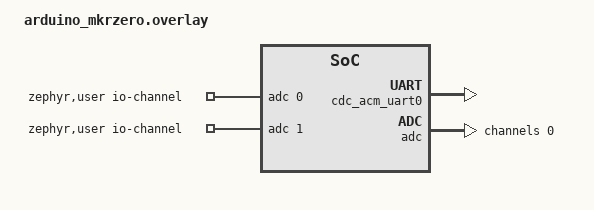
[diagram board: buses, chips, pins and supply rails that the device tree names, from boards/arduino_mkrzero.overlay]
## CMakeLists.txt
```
cmake_minimum_required(VERSION 3.20.0)

find_package(Zephyr)
project(desktop_display)

target_sources(app PRIVATE
        src/main.c
        src/drivers/lcd/lcd.c
        src/serialdata.c
)

target_include_directories(app PRIVATE src)
```

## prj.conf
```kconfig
# Enable UART driver
CONFIG_SERIAL=y

# Enable console but use USB CDC-ACM instead of UART
CONFIG_STDOUT_CONSOLE=n
CONFIG_UART_CONSOLE=y
CONFIG_UART_INTERRUPT_DRIVEN=y

# Enable USB device stack
CONFIG_USB_DEVICE_STACK=y
CONFIG_USB_DEVICE_PRODUCT="Arduino MKR Zero"
CONFIG_USB_DEVICE_MANUFACTURER="Zephyr"
CONFIG_USB_DEVICE_PID=0x0001

# Enable logging for debugging
CONFIG_LOG=y
CONFIG_LOG_DEFAULT_LEVEL=3

# Enable GPIO (we'll need this later for LCD)
CONFIG_GPIO=y

CONFIG_ADC=y
CONFIG_ADC_ASYNC=n
CONFIG_ADC_INIT_PRIORITY=99

CONFIG_USB_DEVICE_INITIALIZE_AT_BOOT=n

CONFIG_CBPRINTF_FP_SUPPORT=y
```

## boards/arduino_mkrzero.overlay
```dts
/*
 * Arduino MKR Zero overlay for LCD keypad project
 */

&zephyr_udc0 {
	cdc_acm_uart0 {
		compatible = "zephyr,cdc-acm-uart";
		label = "Zephyr USB CDC-ACM";
	};
};

/ {
	aliases {
		adc0 = &adc;
	};
};

/ {
	zephyr,user {
		/* Reference the ADC channel for keypad reading */
		io-channels = <&adc 0>, <&adc 1>;
	};
};

&adc {
	#address-cells = <1>;
	#size-cells = <0>;
	status = "okay";

	/* ADC channel configuration for keypad */
	channel@0 {
		reg = <0>;
		zephyr,gain = "ADC_GAIN_2";
		zephyr,reference = "ADC_REF_INTERNAL";
		zephyr,acquisition-time = <ADC_ACQ_TIME_DEFAULT>;
		zephyr,input-positive = <PA2B_ADC_AIN0>;
		zephyr,resolution = <10>;
	};

	/* ADC channel configuration for LM35 temperature sensor */
//	channel@1 {
//		reg = <1>;
//		zephyr,gain = "ADC_GAIN_1";
//		zephyr,reference = "ADC_REF_VDD_1_2";
//		zephyr,acquisition-time = <ADC_ACQ_TIME_DEFAULT>;
//		zephyr,input-positive = <PB2B_ADC_AIN10>;
//		zephyr,resolution = <10>;
//	};
};
```

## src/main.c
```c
 /* LCD Keypad Display for Arduino MKR Zero using Zephyr RTOS
 *
 * Displays the most recently pressed button on the LCD
 */

#include <zephyr/kernel.h>
#include <zephyr/device.h>
#include <zephyr/drivers/uart.h>
#include <zephyr/drivers/gpio.h>
#include <zephyr/sys/printk.h>
#include <zephyr/sys/ring_buffer.h>
#include <zephyr/logging/log.h>
#include <zephyr/usb/usb_device.h>
#include <zephyr/drivers/uart/cdc_acm.h>
#include <zephyr/drivers/adc.h>
#include <string.h>
#include "drivers/lcd/lcd.h"
#include "serialdata.h"

#ifndef DEBUGMODE
#define DEBUGMODE
#endif

LOG_MODULE_REGISTER(app, LOG_LEVEL_INF);

/* LCD state */
static lcd_state_t lcd;

/* Size of the ring buffer for CDC ACM RX */
#define RING_BUF_SIZE 256

/* Create a ring buffer for storing received data */
RING_BUF_DECLARE(cdc_rx_rb, RING_BUF_SIZE);

/* Button value ranges based on observed values with pull-down resistor */
#define BUTTON_RIGHT_MAX    200
#define BUTTON_UP_MAX       400
#define BUTTON_DOWN_MAX     550
#define BUTTON_LEFT_MAX     650
#define BUTTON_SELECT_MAX   745
#define BUTTON_NONE_MAX     1023   // Max value for 10-bit resolution

/* Button debouncing parameters */
#define DEBOUNCE_TIME_MS    50      // Time in ms required for stable button reading
#define BUTTON_SAMPLE_MS    10      // Time between button samples/*

/* Device structures */

const struct device *const cdc_dev = DEVICE_DT_GET_ONE(zephyr_cdc_acm_uart);

#ifdef DEBUGMODE
const struct device *const uart_dev = DEVICE_DT_GET(DT_NODELABEL(sercom5));
#endif

/* ADC channel from devicetree */
static const struct adc_dt_spec button_adc_channel = ADC_DT_SPEC_GET_BY_IDX(DT_PATH(zephyr_user), 0);
/* Define ADC sequence for sampling */
int16_t button_adc_buf;
static struct adc_sequence button_sequence = {
    .buffer = &button_adc_buf,
    .buffer_size = sizeof(button_adc_buf),
};

const struct device *porta = DEVICE_DT_GET(DT_NODELABEL(porta));
const struct device *portb = DEVICE_DT_GET(DT_NODELABEL(portb));

const int btn_pin = 20;



/* Initialize the LCD */
static int init_lcd(void)
{
    /* Get GPIO devices */


    if (!device_is_ready(porta) || !device_is_ready(portb)) {
        LOG_ERR("GPIO devices not ready");
        return -ENODEV;
    }

    /* Configure LCD pins according to your wiring:
     * D0 (PA22) -> LCD D4
     * D1 (PA23) -> LCD D5
     * D2 (PA10) -> LCD D6
     * D3 (PA11) -> LCD D7
     * D4 (PB10) -> LCD RS
     * D5 (PB11) -> LCD Enable
     */
    lcd_config_t config = {
        /* RS pin - using PB10 (D4) */
        .rs_gpio_dev = portb,
        .rs_pin = 10,

        /* Enable pin - using PB11 (D5) */
        .enable_gpio_dev = portb,
        .enable_pin = 11,

        /* Data pins - all on PORTA */
        .d4_gpio_dev = porta,
        .d4_pin = 22,  /* D0 */

        .d5_gpio_dev = porta,
        .d5_pin = 23,  /* D1 */

        .d6_gpio_dev = porta,
        .d6_pin = 10,  /* D2 */

        .d7_gpio_dev = porta,
        .d7_pin = 11,  /* D3 */

        /* No separate backlight control pin */
        .backlight_gpio_dev = NULL,
        .backlight_pin = 0xFF,

        /* ADC for buttons will be set up separately */
        .adc_dev = NULL,
        .adc_channel = 0,

        /* LCD dimensions - standard 16x2 LCD */
        .cols = 16,
        .rows = 2
    };

    /* Initialize LCD */
    int ret = lcd_init(&lcd, &config);
    if (ret == 0) {
        /* Show a welcome message */
        lcd_clear(&lcd);
        lcd_print(&lcd, "LCD Initialized");
        lcd_set_cursor(&lcd, 1, 0);
    }

    lcd_create_char(&lcd, 0, temperature_char);
    lcd_create_char(&lcd, 1, memory_char);
    lcd_create_char(&lcd, 2, cpu_char);
    lcd_create_char(&lcd, 3, fan_char1);
    lcd_create_char(&lcd, 4, fan_char2);

    return ret;
}

static int init_adc(void) {
    int ret;
    /* Check if ADC controller is ready */
    if (!adc_is_ready_dt(&button_adc_channel)) {
        LOG_ERR("ADC controller device %s not ready", button_adc_channel.dev->name);
        return -1;
    }

    /* Setup ADC channel */
    ret = adc_channel_setup_dt(&button_adc_channel);
    if (ret < 0) {
        LOG_ERR("Could not setup channel #%d (%d)", button_adc_channel.channel_id, ret);
        return -1;
    }

    /* Initialize ADC sequence */
    ret = adc_sequence_init_dt(&button_adc_channel, &button_sequence);
    if (ret < 0) {
        LOG_ERR("Could not initialize sequence (%d)", ret);
        return -1;
    }
    return 0;
}

/* UART interrupt callback function */
static void cdc_cb(const struct device *dev, void *user_data)
{
    uint8_t byte;

    /* Process all available data in the CDC FIFO */
    while (uart_irq_update(dev) && uart_irq_is_pending(dev)) {
        /* If RX data is available, read it */
        if (uart_irq_rx_ready(dev)) {
            /* Read a single byte */
            if (uart_fifo_read(dev, &byte, 1) == 1) {
                /* Add the byte to our ring buffer */
                ring_buf_put(&cdc_rx_rb, &byte, 1);
            }
        }
    }
}

/* Identify which button is pressed based on ADC value */
static lcd_button_t identify_button(int32_t adc_value)
{
    if (adc_value <= BUTTON_RIGHT_MAX) {
        return BUTTON_RIGHT;
    } else if (adc_value <= BUTTON_UP_MAX) {
        return BUTTON_UP;
    } else if (adc_value <= BUTTON_DOWN_MAX) {
        return BUTTON_DOWN;
    } else if (adc_value <= BUTTON_LEFT_MAX) {
        return BUTTON_LEFT;
    } else if (adc_value <= BUTTON_SELECT_MAX) {
        return BUTTON_SELECT;
    } else {
        return BUTTON_NONE; /* Default to NONE if no other button matches */
    }
}

/* Advanced debounced button detection function */
static lcd_button_t debounce_button(int32_t adc_value, lcd_button_t *last_stable_button)
{
    static lcd_button_t current_button = BUTTON_NONE;
    static lcd_button_t last_button = BUTTON_NONE;
    static uint32_t stable_since = 0;
    static uint8_t stability_counter = 0;
    uint32_t now = k_uptime_get_32();

    /* First, verify the ADC value is within valid overall range */
    if (adc_value < 0 || adc_value > 1023) {
        /* Invalid ADC reading - reject it */
        return *last_stable_button;
    }

    /* Get raw button state from ADC value */
    lcd_button_t raw_button = identify_button(adc_value);

    /* Check if button state changed */
    if (raw_button != last_button) {
        /* Button state changed, reset the stable timer and counter */
        last_button = raw_button;
        stable_since = now;
        stability_counter = 0;
        return *last_stable_button; /* Return last stable state while unstable */
    }

    /* If button state has been stable for DEBOUNCE_TIME_MS */
    if ((now - stable_since) >= DEBOUNCE_TIME_MS) {
        /* Increment stability counter */
        if (stability_counter < 255) {
            stability_counter++;
        }

        /* Only accept state as stable after multiple consistent readings */
        if (stability_counter >= 3) {
            /* We have a stable button state */
            if (raw_button != current_button) {
                current_button = raw_button;
                *last_stable_button = current_button;
            }
        }
    }

    return *last_stable_button;
}

// uint8_t btn_map(lcd_button_t button) {
//     switch (button) {
//         case BUTTON_RIGHT: return 0x01;
//         case BUTTON_UP:    return 0x02;
//         case BUTTON_DOWN:  return 0x03;
//         case BUTTON_LEFT:  return 0x04;
//         case BUTTON_SELECT: return 0x00;
//         default: return 0x00;
//     }
// }

uint8_t btn_map(uint8_t button) {
    switch (button) {
        case 0x00: return 0x01;
        case 0x01:    return 0x02;
        case 0x02:  return 0x03;
        case 0x03:  return 0x04;
        default: return 0x00;
    }
}



int await_host() {
    if (await_host_pc(&cdc_rx_rb, &lcd, cdc_dev)){
        LOG_INF("Host PC Ready");
        return 0;
    }
    LOG_ERR("Something went wrong waiting for host PC");
    return -1;
}

int main(void)
{
    uint8_t byte;
    int ret;
    lcd_button_t current_button = BUTTON_NONE;
    uint32_t curr_btn = 0x00;
    lcd_button_t last_button = BUTTON_NONE;
    lcd_button_t stable_button = BUTTON_NONE;  // For debouncing
    bool diagnostic_mode = false;  // Set to true to show raw ADC values
    bool showing_temp = false;
    bool reset_temp_reading = false;
    gpio_pin_configure(porta, btn_pin, GPIO_INPUT | GPIO_PULL_DOWN);
#ifdef DEBUGMODE
    if (!device_is_ready(uart_dev)) {
        LOG_ERR("UART device (SERCOM5) not ready");
        return -1;
    }
#endif
    /* Initialize USB CDC ACM - proper device tree approach */
    if (!device_is_ready(cdc_dev)) {
        LOG_ERR("CDC ACM device not ready");
        return -1;
    }

    /* Configure CDC ACM interrupt callback */
    uart_irq_callback_set(cdc_dev, cdc_cb);

    /* Enable CDC ACM RX interrupt */
    uart_irq_rx_enable(cdc_dev);

    ret = usb_enable(NULL);
    if (ret != 0) {
        LOG_ERR("Failed to enable USB");
        return -1;
    }

    /* Initialize LCD */
    ret = init_lcd();
    if (ret != 0) {
        LOG_ERR("Failed to initialize LCD: %d", ret);
        return -1;
    }

    ret = init_adc();
    if (ret != 0) {
        LOG_ERR("Failed to initialize ADC: %d", ret);
    }

    // LOG_INF("Testing ADC channels...");
    // while (1) {
    //     test_adc_channels();
    //     k_msleep(10);
    // }

    k_msleep(1000);  // Show initial message for 1 second

    LOG_INF("All devices initialized");

    // Await init command
    if (await_host() == 0){
		LOG_INF("Host PC Ready");
	}
	else {
		LOG_ERR("Something went wrong waiting for host PC");
		return -1;
	}

    lcd_clear(&lcd);
    bool btn_pressed = false;
    /* Main loop */
    while (1) {
        /* If there's data in the ring buffer, process it */
        if (ring_buf_get(&cdc_rx_rb, &byte, 1)) {
            if (!parse_command_from_ring_buf(&cdc_rx_rb, &lcd, &byte) && byte == 0x0E) {
                if (await_host() == 0){
                    LOG_INF("Host PC Ready");
                }
                else {
                    LOG_ERR("Something went wrong waiting for host PC");
                    return -1;
                }
            }
        }

        /* Get button state with debouncing */
        // current_button = debounce_button(raw_value, &stable_button);

        if (gpio_pin_get(porta, btn_pin) && !btn_pressed) {
            LOG_INF("Button pin pressed");
            btn_pressed = true;
            /* Log the button press */
            curr_btn = btn_map(curr_btn);
            uint8_t cmd[4] = {
                0x01,
                0x01,
                curr_btn,
                0x00
            };

            if (curr_btn == 0x04) {
                showing_temp = true;
            }
            else {
                showing_temp = false;
            }

            LOG_INF("Sending command");
            LOG_INF("current button is: %d", cmd[2]);

            send_message(cdc_dev, cmd);
            lcd_clear(&lcd);
            ring_buf_reset(&cdc_rx_rb);
        }
        if (!gpio_pin_get(porta, btn_pin)) {
            btn_pressed = false;
        }

        /* Periodically read temperature (every 500ms or so) */
        if (showing_temp) {
            lcd_home(&lcd);
            lcd_set_cursor(&lcd, 0, 0);
            lcd_print(&lcd, "Room Temperature");
            lcd_set_cursor(&lcd, 1, 5);
            lcd_write_char(&lcd, 0);
            static uint32_t temp_counter = 1;
            /* Configure and read temperature ADC */

            (void)adc_sequence_init_dt(&button_adc_channel, &button_sequence);
            int err = adc_read_dt(&button_adc_channel, &button_sequence);
            int32_t raw_value = button_adc_buf;
            err = adc_raw_to_millivolts_dt(&button_adc_channel, &raw_value);

            float temp_reading;
            float celsius;
            if (err > 0) {
                celsius = (raw_value / 10.0f);
            }
            else {
                celsius = (raw_value * 330.0f) / (1024.0f * 5.0f);
            }

            if (reset_temp_reading) {
                temp_reading = (celsius * (9.0f/5.0f)) + 32.0f;
            }
            else {
                temp_reading = (temp_reading / (float)temp_counter) + (((celsius * (9.0f/5.0f)) + 32.0f) / (float)temp_counter);
            }


            if (++temp_counter >= 151) {
                temp_counter = 1;
                reset_temp_reading = true;
                lcd_set_cursor(&lcd, 1, 6);
                lcd_print(&lcd, "         ");


                /* Process temperature reading as needed */

                LOG_INF("Temperature: %.1fF", temp_reading);
                lcd_set_cursor(&lcd, 1, 6);
                char temp_str[12];
                sprintf(temp_str, "%.1fF", temp_reading);
                lcd_print(&lcd, temp_str);
                k_msleep(100);
            }
        }


        /* Small delay for button sampling */
        k_msleep(BUTTON_SAMPLE_MS);
    }

    return 0;
}
```

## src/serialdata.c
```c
//
// Created by adamr on 3/25/25.
//

#include "serialdata.h"
#include <zephyr/drivers/uart.h>
#include <zephyr/device.h>
#include <zephyr/logging/log.h>

LOG_MODULE_REGISTER(serialdata, LOG_LEVEL_DBG);

#define DEBUG false

void log_received_data(uint8_t *command) {
    char dbgBuff[50] = "Received Data (hex): ";
    for (uint8_t i = 0; i < command[1]+3; i++) {
        sprintf(dbgBuff + strlen(dbgBuff), "%02x ", command[i]);
    }
    LOG_DBG("%s", dbgBuff);
}

uint8_t calculate_checksum(uint8_t *data) {
    uint8_t checksum = *data;
    for (uint8_t i = 1; i < *(data + 1) + 2; i++) {
        if (DEBUG) {
            LOG_DBG("Byte is %02x, Checksum is %02x", *(data + i), checksum);
        }
        checksum ^= *(data + i);
    }
    return checksum;
}

bool verify_checksum(uint8_t *data) {
    // if (data[1] < 1){
    //   return false;
    // }
    uint8_t received_checksum = data[data[1] + 2];
    uint8_t calc_checksum = calculate_checksum(data);

    return received_checksum == calc_checksum;
}

void send_message(const struct device *uart_dev, uint8_t *data) {

    uint8_t checksum = calculate_checksum(data);
    data[data[1]+2] = checksum;
    LOG_INF("Sending message");

    for(size_t i = 0; i <= data[1] + 2; i++) {
        LOG_INF("Sending %02x", data[i]);
        uart_poll_out(uart_dev, data[i]);
        k_busy_wait(100);
    }
}

bool parse_command_from_ring_buf(struct ring_buf *buf, lcd_state_t *lcd, uint8_t *cmdByte){
    uint8_t dataLength;
    ring_buf_get(buf, &dataLength, 1);
    LOG_INF("Command received: %u", *cmdByte);
    if (*cmdByte == 0x00) {
        if (dataLength == 0x00) {
            return true;
        }
        return false;
    }

    uint8_t data[dataLength+4];
    data[0] = *cmdByte;
    data[1] = dataLength;
    for (uint8_t i = 0; i < dataLength + 1; i++) {
        uint8_t c;
        ring_buf_get(buf, &c, 1);
        data[i+2] = c;
    }

    dispatch_command(lcd, data);
    return false;
}

bool dispatch_command(lcd_state_t *lcd, uint8_t *command) {
    if (DEBUG) {
        log_received_data(command);
        LOG_DBG("Command is %02x", *command);
    }

    if (!verify_checksum(command)) {
        LOG_INF("Received invalid checksum");
        return false;
    }

    LOG_INF("Command verified");
    switch (*command) {
        case DATE_CMD:
            handle_date_cmd(lcd, command);
            break;
        case TIME_CMD:
            handle_time_cmd(lcd, command);
            break;
        case CPU_TEMP_CMD:
            handle_cpu_temp_cmd(lcd, command);
            break;
        case CPU_USE_CMD:
            handle_cpu_usage_cmd(lcd, command);
            break;
        case MEM_USE_CMD:
            handle_memory_cmd(lcd, command);
            break;
        case GPU_TEMP_CMD:
            handle_gpu_temp_cmd(lcd, command);
            break;
        case GPU_USE_CMD:
            handle_gpu_usage_cmd(lcd, command);
            break;
        case GPU_FAN_SPEED_CMD:
            handle_gpu_fan_speed_cmd(lcd, command);
            break;
        case VRAM_USE_CMD:
            handle_vram_cmd(lcd, command);
            break;
        case AUDIO_CMD:
            not_implemented_display(lcd, command);
            break;
        case CLEAR_SCREEN_CMD:
            LOG_INF("Clearing screen");
            lcd_clear(lcd);
            break;
        case CLOSE_CONNECTION_CMD:
            return false;
        default: return true;
    }
    return true;
}

void handle_date_cmd(lcd_state_t *lcd, uint8_t *command) {
    lcd_set_cursor(lcd, DATE_ROW, DATE_COL);
    char printStr[14];
    sprintf(printStr, "%02u/%02u/%u", command[2], command[3], (command[4] << 8) | command[5]);
    LOG_INF("Received date: %s", printStr);
    lcd_print(lcd, printStr);
}

void handle_time_cmd(lcd_state_t *lcd, uint8_t *command) {
    lcd_set_cursor(lcd, TIME_ROW, TIME_COL);
    char printStr[11] = "HH:MM AA";
    char amPm[3];
    if (command[4]){
        sprintf(amPm, "PM");
    }
    else{
        sprintf(amPm, "AM");
    }
    sprintf(printStr, "%02u:%02u %s", command[2], command[3], amPm);
    LOG_INF("Received time: %s", printStr);
    lcd_print(lcd, printStr);
}

void handle_cpu_temp_cmd(lcd_state_t *lcd, uint8_t *command) {
    lcd_set_cursor(lcd, CPU_TEMP_ROW, CPU_TEMP_COL);
    lcd_write_char(lcd, 0);
    lcd_set_cursor(lcd, CPU_TEMP_ROW, CPU_TEMP_COL + 1);
    char tempStr[10] = {0};
    sprintf(tempStr, "%dC", command[2]);
    LOG_INF("Received CPU temperature: %s", tempStr);
    lcd_print(lcd, tempStr);
}

void handle_cpu_usage_cmd(lcd_state_t *lcd, uint8_t *command) {
    lcd_set_cursor(lcd, CPU_USE_ROW, CPU_USE_COL);
    lcd_write_char(lcd, 2);
    lcd_set_cursor(lcd, CPU_USE_ROW, CPU_USE_COL + 1);
    char useStr[10] = {0};
    sprintf(useStr, "%02d%%", command[2]);
    LOG_INF("Received CPU usage: %s", useStr);
    lcd_print(lcd, useStr);
}

void handle_memory_cmd(lcd_state_t *lcd, uint8_t *command) {
    lcd_set_cursor(lcd, MEM_USE_ROW, MEM_USE_COL);
    lcd_write_char(lcd, 1);
    lcd_set_cursor(lcd, MEM_USE_ROW, MEM_USE_COL + 1);
    char memStr[10] = {0};
    sprintf(memStr, "%d%%", command[2]);
    LOG_INF("Received memory usage: %s", memStr);
    lcd_print(lcd, memStr);
}

void handle_gpu_temp_cmd(lcd_state_t *lcd, uint8_t *command) {
    lcd_set_cursor(lcd, GPU_TEMP_ROW, GPU_TEMP_COL);
    lcd_write_char(lcd, 0);
    lcd_set_cursor(lcd, GPU_TEMP_ROW, GPU_TEMP_COL + 1);
    char tempStr[10] = {0};
    sprintf(tempStr, "%dC", command[2]);
    LOG_INF("Received GPU temperature: %s", tempStr);
    lcd_print(lcd, tempStr);
}

void handle_gpu_usage_cmd(lcd_state_t *lcd, uint8_t *command) {
    lcd_set_cursor(lcd, GPU_USE_ROW, GPU_USE_COL);
    lcd_write_char(lcd, 2);
    lcd_set_cursor(lcd, GPU_USE_ROW, GPU_USE_COL + 1);
    char useStr[10] = {0};
    sprintf(useStr, "%02d%%", command[2]);
    LOG_INF("Received GPU usage: %s", useStr);
    lcd_print(lcd, useStr);
}

void handle_gpu_fan_speed_cmd(lcd_state_t *lcd, uint8_t *command) {
    lcd_set_cursor(lcd, GPU_FAN_SPEED_ROW, GPU_FAN_SPEED_COL);
    // if (fan_icon_switch) {
    //     lcd_write_char(lcd, 3);
    // }
    // else {
    //     lcd_write_char(lcd, 4);
    // }
    // fan_icon_switch = !fan_icon_switch;
    lcd_write_char(lcd, 3);
    lcd_set_cursor(lcd, GPU_FAN_SPEED_ROW, GPU_FAN_SPEED_COL + 1);
    char speedStr[16] = {0};
    sprintf(speedStr, "%dRPM", command[2] << 8 | command[3]);
    LOG_INF("Received GPU fan speed: %s", speedStr);
    lcd_print(lcd, speedStr);
}

void handle_vram_cmd(lcd_state_t *lcd, uint8_t *command) {
    lcd_set_cursor(lcd, VRAM_USE_ROW, VRAM_USE_COL);
    lcd_write_char(lcd, 1);
    lcd_set_cursor(lcd, VRAM_USE_ROW, VRAM_USE_COL + 1);
    char vramStr[10] = {0};
    sprintf(vramStr, "%02d%%", command[2]);
    LOG_INF("Received VRAM usage: %s", vramStr);
    lcd_print(lcd, vramStr);
}

void handle_song_cmd(lcd_state_t *lcd, uint8_t *command) {
    lcd_set_cursor(lcd, 0, 0);
    char printStr[17];
    for (uint8_t i = 2; i < command[1]+2; i++) {
        sprintf(printStr + strlen(printStr), "%c", command[i]);
    }
    LOG_INF("Received song: %s", printStr);
    lcd_print(lcd, printStr);
}

void not_implemented_display(lcd_state_t *lcd, uint8_t *command) {
    lcd_set_cursor(lcd, 0, 0);
    char printStr[19] = {0};
    for (uint8_t i = 2; i < command[1]+1; i++) {
        sprintf(printStr + strlen(printStr), "%c", command[i]);
    }

    LOG_INF("Received data (str): %s", printStr);
    lcd_print(lcd, printStr);

    lcd_set_cursor(lcd, 1, 0);
    sprintf(printStr, "Page: %u", command[command[1] + 1]);
    char c;
    switch (command[command[1] + 1]) {
        case 0x01:
            c = '1';
            break;
        case 0x02:
            c = '2';
            break;
        case 0x03:
            c = '3';
            break;
        default:
            c = '0';
            break;
    }
    lcd_write_char(lcd, c);
}

void clear_screen_cmd(lcd_state_t *lcd) {
    LOG_INF("Clearing screen");
    lcd_clear(lcd);
}

bool await_host_pc(struct ring_buf *buf, lcd_state_t *lcd, const struct device *cdc_dev) {
	uint8_t byte;
	lcd_clear(lcd);
    lcd_home(lcd);
    lcd_print(lcd, "Device Ready");
    lcd_set_cursor(lcd, 1, 0);
    lcd_print(lcd, "Awaiting Host PC");
	while (1){
		LOG_INF("Waiting for command");
        if (ring_buf_get(buf, &byte, 1)) {
            LOG_INF("Buffer has bytes");
            if (parse_command_from_ring_buf(buf, lcd, &byte)) {
                LOG_INF("Got ready command from host PC");
                lcd_clear(lcd);
                lcd_home(lcd);
                lcd_print(lcd, "Host Ready");
                lcd_set_cursor(lcd, 1, 0);
                lcd_print(lcd, "Sending ready");
                LOG_INF("Sending ready message back to host");
                for (size_t i = 0; i < 2; i++) {
                    const uint8_t readyCmd[2] = {0x00, 0x00};
                    uart_poll_out(cdc_dev, readyCmd[i]);
                }
                uint8_t cmd[4] = {
                    0x01,
                    0x01,
                    0x00,
                    0x00
                };
                send_message(cdc_dev, cmd);
                return true;
            }
        }
        k_msleep(500);
	}
	return false; // Should never be hit
}

void display_ambient_temperature(lcd_state_t *lcd, float temperature) {
    lcd_clear(lcd);

    // Display title
    lcd_set_cursor(lcd, AMBIENT_TEMP_TITLE_ROW, AMBIENT_TEMP_TITLE_COL);
    lcd_write_char(lcd, 0); // Thermometer icon
    lcd_print(lcd, "Ambient Temp");

    // Display temperature with thermometer icon
    lcd_set_cursor(lcd, AMBIENT_TEMP_ROW, AMBIENT_TEMP_COL);

    // Format temperature with 1 decimal place
    char temp_str[12];
    sprintf(temp_str, " %.1f C", temperature);
    lcd_print(lcd, temp_str);

    LOG_INF("Displayed ambient temperature: %.1f°C", temperature);
}
```

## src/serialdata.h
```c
//
// Created by adamr on 3/25/25.
//

#ifndef SERIALDATA_H
#define SERIALDATA_H
#endif //SERIALDATA_H

#include <zephyr/kernel.h>
#include <zephyr/device.h>
#include <zephyr/drivers/gpio.h>
#include "drivers/lcd/lcd.h"

#define READY_CMD 0x00
#define PAGE_CMD 0x01

#define DATE_CMD 0x02
#define DATE_ROW 0
#define DATE_COL 3

#define TIME_CMD 0x03
#define TIME_ROW 1
#define TIME_COL 4

#define CPU_TEMP_CMD 0x04
#define CPU_TEMP_ROW 0
#define CPU_TEMP_COL 2

#define CPU_USE_CMD 0x05
#define CPU_USE_ROW 0
#define CPU_USE_COL 10

#define CPU_FAN_SPEED_CMD 0x06

#define GPU_TEMP_CMD 0x07
#define GPU_TEMP_ROW 0
#define GPU_TEMP_COL 2

#define GPU_USE_CMD 0x08
#define GPU_USE_ROW 0
#define GPU_USE_COL 10

#define GPU_FAN_SPEED_CMD 0x09
#define GPU_FAN_SPEED_ROW 1
#define GPU_FAN_SPEED_COL 0

#define MEM_USE_CMD 0x0A
#define MEM_USE_ROW 1
#define MEM_USE_COL 6

#define AUDIO_CMD 0x0B

#define VRAM_USE_CMD 0x0C
#define VRAM_USE_ROW 1
#define VRAM_USE_COL 10

#define CLEAR_SCREEN_CMD 0x0D
#define CLOSE_CONNECTION_CMD 0x0E

#define AMBIENT_TEMP_TITLE_ROW 0
#define AMBIENT_TEMP_TITLE_COL 3
#define AMBIENT_TEMP_ROW 1
#define AMBIENT_TEMP_COL 3

#define R_PAGE 0x00
#define U_PAGE 0x01
#define D_PAGE 0x02
#define L_PAGE 0x03
#define S_PAGE 0x04



uint8_t calculate_checksum(uint8_t *data);

bool verify_checksum(uint8_t *data);

void send_message(const struct device *uart_dev, uint8_t *data);

bool parse_command_from_ring_buf(struct ring_buf *buf, lcd_state_t *lcd, uint8_t *cmdByte);

bool dispatch_command(lcd_state_t *lcd, uint8_t *command);

void handle_date_cmd(lcd_state_t *lcd, uint8_t *command);

void handle_time_cmd(lcd_state_t *lcd, uint8_t *command);

void handle_cpu_temp_cmd(lcd_state_t *lcd, uint8_t *command);

void handle_cpu_usage_cmd(lcd_state_t *lcd, uint8_t *command);

void handle_memory_cmd(lcd_state_t *lcd, uint8_t *command);

void handle_gpu_temp_cmd(lcd_state_t *lcd, uint8_t *command);

void handle_gpu_usage_cmd(lcd_state_t *lcd, uint8_t *command);

void handle_gpu_fan_speed_cmd(lcd_state_t *lcd, uint8_t *command);

void handle_vram_cmd(lcd_state_t *lcd, uint8_t *command);

void handle_song_cmd(lcd_state_t *lcd, uint8_t *command);

void not_implemented_display(lcd_state_t *lcd, uint8_t *command);

void clear_screen_cmd(lcd_state_t *lcd);

void close_connection_cmd(lcd_state_t *lcd);

bool await_host_pc(struct ring_buf *buf, lcd_state_t *lcd, const struct device *cdc_dev);

void display_ambient_temperature(lcd_state_t *lcd, float temperature);
```
